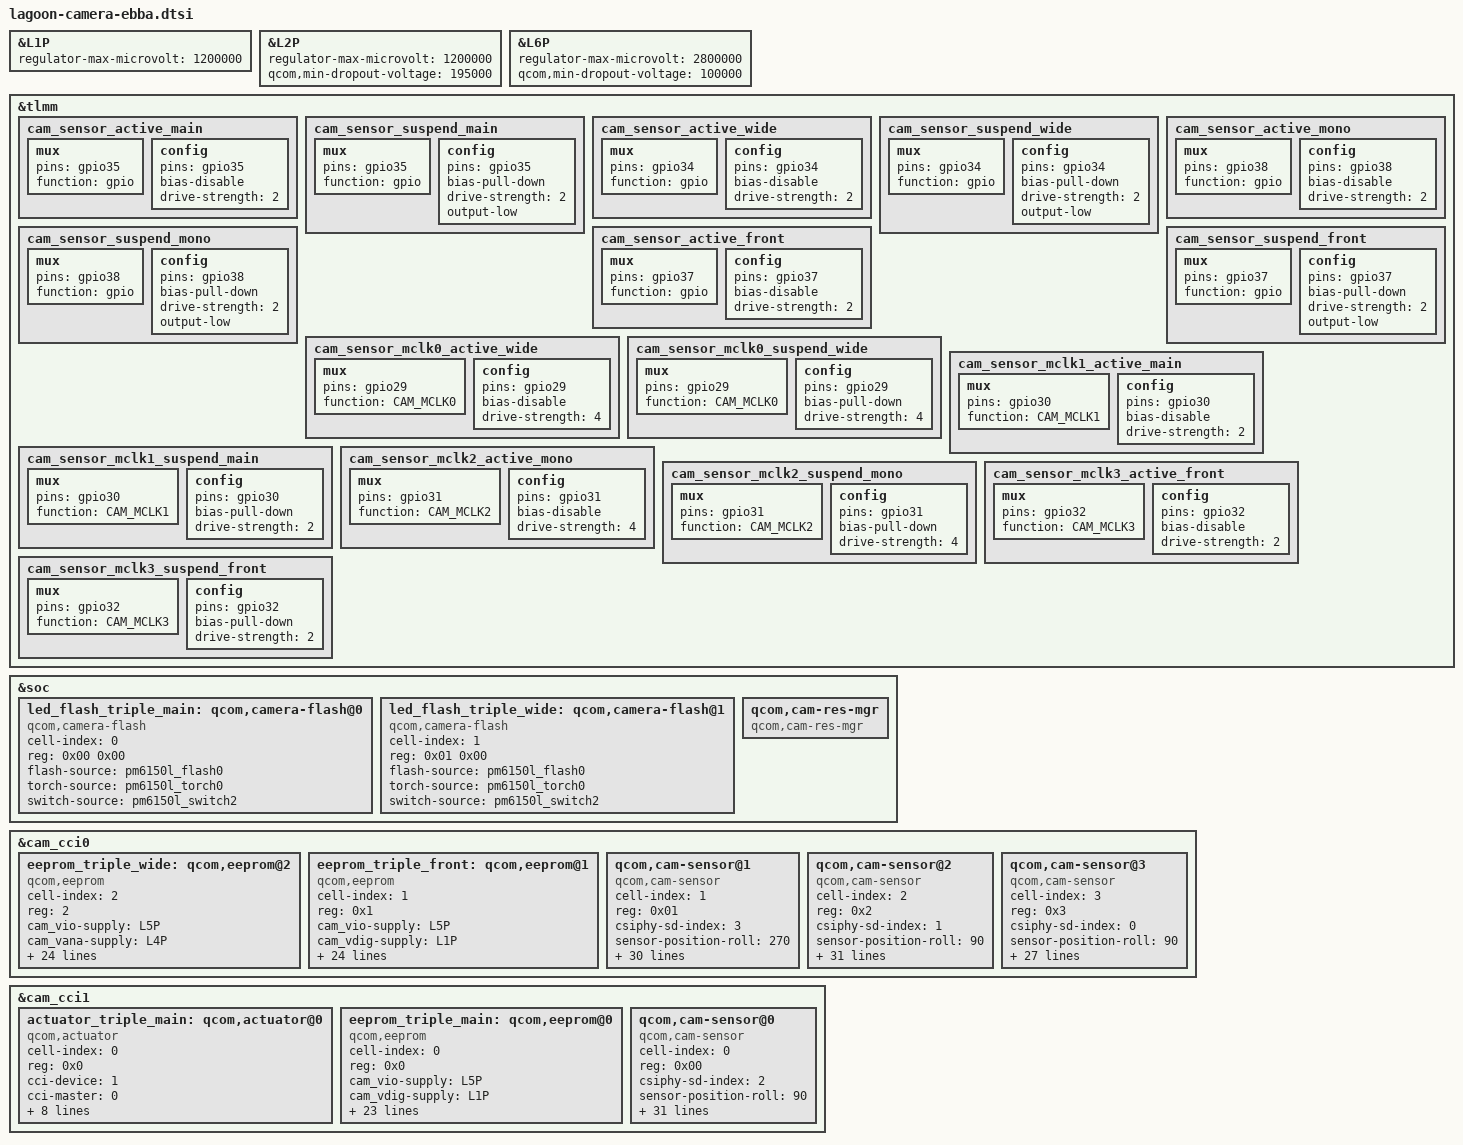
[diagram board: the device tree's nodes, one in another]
#include <dt-bindings/clock/qcom,camcc-lagoon.h>
/*
&pm8008_regulators {
    vdd_l6-supply = <&BOB>;
};
*/
&L1P {
    regulator-max-microvolt = <1200000>;
};

&L2P {
    regulator-max-microvolt = <1200000>;
    qcom,min-dropout-voltage = <195000>;
};

&L6P {
    regulator-max-microvolt = <2800000>;
    qcom,min-dropout-voltage = <100000>;
};

&tlmm {
	cam_sensor_active_main: cam_sensor_active_main {
		/* RESET REAR*/
		mux {
			pins = "gpio35";
			function = "gpio";
		};

		config {
			pins = "gpio35";
			bias-disable; /* No PULL */
			drive-strength = <2>; /* 2 MA */
		};
	};

	cam_sensor_suspend_main: cam_sensor_suspend_main {
		/* RESET REAR*/
		mux {
			pins = "gpio35";
			function = "gpio";
		};

		config {
			pins = "gpio35";
			bias-pull-down; /* PULL DOWN */
			drive-strength = <2>; /* 2 MA */
			output-low;
		};
	};

	cam_sensor_active_wide: cam_sensor_active_wide {
		/* RESET REARAUX */
		mux {
			pins = "gpio34";
			function = "gpio";
		};

		config {
			pins = "gpio34";
			bias-disable; /* No PULL */
			drive-strength = <2>; /* 2 MA */
		};
	};

	cam_sensor_suspend_wide: cam_sensor_suspend_wide {
		/* RESET REARAUX */
		mux {
			pins = "gpio34";
			function = "gpio";
		};

		config {
			pins = "gpio34";
			bias-pull-down; /* PULL DOWN */
			drive-strength = <2>; /* 2 MA */
			output-low;
		};
	};

	cam_sensor_active_mono: cam_sensor_active_mono {
		/* RESET REARAUX1 */
		mux {
			pins = "gpio38";
			function = "gpio";
		};

		config {
			pins = "gpio38";
			bias-disable; /* No PULL */
			drive-strength = <2>; /* 2 MA */
		};
	};

	cam_sensor_suspend_mono: cam_sensor_suspend_mono {
		/* RESET REARAUX1 */
		mux {
			pins = "gpio38";
			function = "gpio";
		};

		config {
			pins = "gpio38";
			bias-pull-down; /* PULL DOWN */
			drive-strength = <2>; /* 2 MA */
			output-low;
		};
	};

	cam_sensor_active_front: cam_sensor_active_front {
		/* RESET FRONT */
		mux {
			pins = "gpio37";
			function = "gpio";
		};

		config {
			pins = "gpio37";
			bias-disable; /* No PULL */
			drive-strength = <2>; /* 2 MA */
		};
	};

	cam_sensor_suspend_front: cam_sensor_suspend_front {
		/* RESET FRONT */
		mux {
			pins = "gpio37";
			function = "gpio";
		};

		config {
			pins = "gpio37";
			bias-pull-down; /* PULL DOWN */
			drive-strength = <2>; /* 2 MA */
			output-low;
		};
	};

	cam_sensor_mclk0_active_wide: cam_sensor_mclk0_active_wide {
		/* MCLK0 */
		mux {
			pins = "gpio29";
			function = "CAM_MCLK0";
		};

		config {
			pins = "gpio29";
			bias-disable; /* No PULL */
			drive-strength = <4>; /* 4 MA */
		};
	};

	cam_sensor_mclk0_suspend_wide: cam_sensor_mclk0_suspend_wide {
		/* MCLK0 */
		mux {
			pins = "gpio29";
			function = "CAM_MCLK0";
		};

		config {
			pins = "gpio29";
			bias-pull-down; /* PULL DOWN */
			drive-strength = <4>; /* 4 MA */
		};
	};

	cam_sensor_mclk1_active_main: cam_sensor_mclk1_active_main {
		/* MCLK1 */
		mux {
			pins = "gpio30";
			function = "CAM_MCLK1";
		};

		config {
			pins = "gpio30";
			bias-disable; /* No PULL */
			drive-strength = <2>; /* 2 MA */
		};
	};

	cam_sensor_mclk1_suspend_main: cam_sensor_mclk1_suspend_main {
		/* MCLK1 */
		mux {
			pins = "gpio30";
			function = "CAM_MCLK1";
		};

		config {
			pins = "gpio30";
			bias-pull-down; /* PULL DOWN */
			drive-strength = <2>; /* 2 MA */
		};
	};

	cam_sensor_mclk2_active_mono: cam_sensor_mclk2_active_mono {
		/* MCLK2 */
		mux {
			pins = "gpio31";
			function = "CAM_MCLK2";
		};

		config {
			pins = "gpio31";
			bias-disable; /* No PULL */
			drive-strength = <4>; /* 4 MA */
		};
	};

	cam_sensor_mclk2_suspend_mono: cam_sensor_mclk2_suspend_mono {
		/* MCLK2 */
		mux {
			pins = "gpio31";
			function = "CAM_MCLK2";
		};

		config {
			pins = "gpio31";
			bias-pull-down; /* PULL DOWN */
			drive-strength = <4>; /* 4 MA */
		};
	};

	cam_sensor_mclk3_active_front: cam_sensor_mclk3_active_front {
		/* MCLK3 */
		mux {
			pins = "gpio32";
			function = "CAM_MCLK3";
		};

		config {
			pins = "gpio32";
			bias-disable; /* No PULL */
			drive-strength = <2>; /* 2 MA */
		};
	};

	cam_sensor_mclk3_suspend_front: cam_sensor_mclk3_suspend_front {
		/* MCLK3 */
		mux {
			pins = "gpio32";
			function = "CAM_MCLK3";
		};

		config {
			pins = "gpio32";
			bias-pull-down; /* PULL DOWN */
			drive-strength = <2>; /* 2 MA */
		};
	};
};

&soc {
	led_flash_triple_main: qcom,camera-flash@0 {
		cell-index = <0>;
		reg = <0x00 0x00>;
		compatible = "qcom,camera-flash";
		flash-source = <&pm6150l_flash0>;
		torch-source = <&pm6150l_torch0>;
		switch-source = <&pm6150l_switch2>;
		status = "ok";
	};

	led_flash_triple_wide: qcom,camera-flash@1 {
		cell-index = <1>;
		reg = <0x01 0x00>;
		compatible = "qcom,camera-flash";
		flash-source = <&pm6150l_flash0>;
		torch-source = <&pm6150l_torch0>;
		switch-source = <&pm6150l_switch2>;
		status = "ok";
	};

	qcom,cam-res-mgr {
		compatible = "qcom,cam-res-mgr";
		status = "ok";
	};
};

&cam_cci0 {
	eeprom_triple_wide: qcom,eeprom@2 {
		cell-index = <2>;
		reg = <2>;
		compatible = "qcom,eeprom";
		cam_vio-supply = <&L5P>;
		cam_vana-supply = <&L4P>;
		cam_vdig-supply = <&L2P>;
		cam_clk-supply = <&cam_cc_titan_top_gdsc>;
		regulator-names = "cam_vio", "cam_vana", "cam_vdig",
			"cam_clk";
		rgltr-cntrl-support;
		rgltr-min-voltage = <1800000 2800000 1200000 0>;
		rgltr-max-voltage = <1800000 2800000 1200000 0>;
		rgltr-load-current = <2000000 2000000 2000000 0>;
		gpio-no-mux = <0>;
		pinctrl-names = "cam_default", "cam_suspend";
		pinctrl-0 = <&cam_sensor_mclk0_active_wide
				 &cam_sensor_active_wide>;
		pinctrl-1 = <&cam_sensor_mclk0_suspend_wide
				 &cam_sensor_suspend_wide>;
		gpios = <&tlmm 29 0>,
			<&tlmm 34 0>;
		gpio-reset = <1>;
		gpio-req-tbl-num = <0 1>;
		gpio-req-tbl-flags = <1 0>;
		gpio-req-tbl-label = "CAMIF_MCLK0",
					"CAM_RESET2";
		sensor-mode = <0>;
		cci-device = <0>;
		cci-master = <1>;
		status = "ok";
		clocks = <&camcc CAM_CC_MCLK0_CLK>;
		clock-names = "cam_clk";
		clock-cntl-level = "turbo";
		clock-rates = <19200000>;
	};

	eeprom_triple_front: qcom,eeprom@1 {
		cell-index = <1>;
		reg = <0x1>;
		compatible = "qcom,eeprom";
		cam_vio-supply = <&L5P>;
		cam_vdig-supply = <&L1P>;
		cam_clk-supply = <&cam_cc_titan_top_gdsc>;
		regulator-names = "cam_vio", "cam_vdig",
			"cam_clk";
		rgltr-cntrl-support;
		pwm-switch;
		rgltr-min-voltage = <1800000 1100000 0>;
		rgltr-max-voltage = <1800000 1100000 0>;
		rgltr-load-current = <2000000 2000000 0>;
		gpio-no-mux = <0>;
		pinctrl-names = "cam_default", "cam_suspend";
		pinctrl-0 = <&cam_sensor_mclk3_active_front
			&cam_sensor_active_front>;
		pinctrl-1 = <&cam_sensor_mclk3_suspend_front
			&cam_sensor_suspend_front>;
		gpios = <&tlmm 32 0>,
			<&tlmm 37 0>;
		gpio-reset = <1>;
		gpio-req-tbl-num = <0 1>;
		gpio-req-tbl-flags = <1 0>;
		gpio-req-tbl-label = "CAMIF_MCLK3",
					"CAM_RESET1";
		sensor-position = <1>;
		sensor-mode = <0>;
		cci-device = <0>;
		cci-master = <0>;
		status = "ok";
		clocks = <&camcc CAM_CC_MCLK3_CLK>;
		clock-names = "cam_clk";
		clock-cntl-level = "turbo";
		clock-rates = <19200000>;
	};

	/* front sensor */
	qcom,cam-sensor@1 {
		cell-index = <1>;
		compatible = "qcom,cam-sensor";
		reg = <0x01>;
		csiphy-sd-index = <3>;
		sensor-position-roll = <270>;
		sensor-position-pitch = <0>;
		sensor-position-yaw = <0>;
		eeprom-src = <&eeprom_triple_front>;
		cam_vio-supply = <&L5P>;
		cam_vana-supply = <&L7P>;
		cam_vdig-supply = <&L1P>;
		cam_clk-supply = <&cam_cc_titan_top_gdsc>;
		regulator-names = "cam_vio", "cam_vana", "cam_vdig",
			"cam_clk";
		rgltr-cntrl-support;
		pwm-switch;
		rgltr-min-voltage = <1800000 2800000 1100000 0>;
		rgltr-max-voltage = <1800000 2800000 1100000 0>;
		rgltr-load-current = <2000000 2000000 2000000 0>;
		gpio-no-mux = <0>;
		pinctrl-names = "cam_default", "cam_suspend";
		pinctrl-0 = <&cam_sensor_mclk3_active_front
			&cam_sensor_active_front>;
		pinctrl-1 = <&cam_sensor_mclk3_suspend_front
			&cam_sensor_suspend_front>;
		gpios = <&tlmm 32 0>,
			<&tlmm 37 0>;
		gpio-reset = <1>;
		gpio-req-tbl-num = <0 1>;
		gpio-req-tbl-flags = <1 0>;
		gpio-req-tbl-label = "CAMIF_MCLK3",
					"CAM_RESET1";
		sensor-mode = <0>;
		cci-device = <0>;
		cci-master = <0>;
		status = "ok";
		clocks = <&camcc CAM_CC_MCLK3_CLK>;
		clock-names = "cam_clk";
		clock-cntl-level = "turbo";
		clock-rates = <19200000>;
	};

	/* wide sensor */
	qcom,cam-sensor@2 {
		cell-index = <2>;
		compatible = "qcom,cam-sensor";
		reg = <0x2>;
		csiphy-sd-index = <1>;
		sensor-position-roll = <90>;
		sensor-position-pitch = <0>;
		sensor-position-yaw = <180>;
		eeprom-src = <&eeprom_triple_wide>;
		led-flash-src = <&led_flash_triple_wide>;
		cam_vio-supply = <&L5P>;
		cam_vana-supply = <&L4P>;
		cam_vdig-supply = <&L2P>;
		cam_clk-supply = <&cam_cc_titan_top_gdsc>;
		regulator-names = "cam_vio", "cam_vana", "cam_vdig",
			"cam_clk";
		rgltr-cntrl-support;
		pwm-switch;
		rgltr-min-voltage = <1800000 2800000 1200000 0>;
		rgltr-max-voltage = <1800000 2800000 1200000 0>;
		rgltr-load-current = <2000000 2000000 2000000 0>;
		gpio-no-mux = <0>;
		pinctrl-names = "cam_default", "cam_suspend";
		pinctrl-0 = <&cam_sensor_mclk0_active_wide
				 &cam_sensor_active_wide>;
		pinctrl-1 = <&cam_sensor_mclk0_suspend_wide
				 &cam_sensor_suspend_wide>;
		gpios = <&tlmm 29 0>,
			<&tlmm 34 0>;
		gpio-reset = <1>;
		gpio-req-tbl-num = <0 1>;
		gpio-req-tbl-flags = <1 0>;
		gpio-req-tbl-label = "CAMIF_MCLK0",
					"CAM_RESET2";
		sensor-mode = <0>;
		cci-device = <0>;
		cci-master = <1>;
		status = "ok";
		clocks = <&camcc CAM_CC_MCLK0_CLK>;
		clock-names = "cam_clk";
		clock-cntl-level = "turbo";
		clock-rates = <19200000>;
	};

	/* mono sensor */
	qcom,cam-sensor@3 {
		cell-index = <3>;
		compatible = "qcom,cam-sensor";
		reg = <0x3>;
		csiphy-sd-index = <0>;
		sensor-position-roll = <90>;
		sensor-position-pitch = <0>;
		sensor-position-yaw = <180>;
		cam_vio-supply = <&L5P>;
		cam_vana-supply = <&L4P>;
		cam_clk-supply = <&cam_cc_titan_top_gdsc>;
		regulator-names = "cam_vio", "cam_vana", "cam_clk";
		rgltr-cntrl-support;
		pwm-switch;
		rgltr-min-voltage = <1800000 2800000 0>;
		rgltr-max-voltage = <1800000 2800000 0>;
		rgltr-load-current = <2000000 2000000 0>;
		gpio-no-mux = <0>;
		pinctrl-names = "cam_default", "cam_suspend";
		pinctrl-0 = <&cam_sensor_mclk2_active_mono
				&cam_sensor_active_mono>;
		pinctrl-1 = <&cam_sensor_mclk2_suspend_mono
				&cam_sensor_suspend_mono>;
		gpios = <&tlmm 31 0>,
			<&tlmm 38 0>;
		gpio-standby = <1>;//PWDN
		gpio-req-tbl-num = <0 1>;
		gpio-req-tbl-flags = <1 0>;
		gpio-req-tbl-label = "CAMIF_MCLK2",
					"CAM_STANDBY";
		sensor-mode = <0>;
		cci-device = <0>;
		cci-master = <1>;
		status = "ok";
		clocks = <&camcc CAM_CC_MCLK2_CLK>;
		clock-names = "cam_clk";
		clock-cntl-level = "turbo";
		clock-rates = <19200000>;
	};
};

&cam_cci1 {
	actuator_triple_main: qcom,actuator@0 {
		cell-index = <0>;
		reg = <0x0>;
		compatible = "qcom,actuator";
		cci-device = <1>;
		cci-master = <0>;
		cam_vio-supply = <&L5P>;
		cam_vaf-supply = <&L6P>;
		regulator-names = "cam_vio", "cam_vaf";
		rgltr-cntrl-support;
		need-check-pid;
		rgltr-min-voltage = <1800000 2800000>;
		rgltr-max-voltage = <1800000 2800000>;
		rgltr-load-current = <2000000 100000>;
		status = "ok";
	};

	eeprom_triple_main: qcom,eeprom@0 {
		cell-index = <0>;
		reg = <0x0>;
		compatible = "qcom,eeprom";
		cam_vio-supply = <&L5P>;
		cam_vdig-supply = <&L1P>;
		cam_clk-supply = <&cam_cc_titan_top_gdsc>;
		regulator-names = "cam_vio", "cam_vdig",
			"cam_clk";
		rgltr-cntrl-support;
		rgltr-min-voltage = <1800000 1100000 0>;
		rgltr-max-voltage = <1800000 1100000 0>;
		rgltr-load-current = <2000000 2000000 0>;
		gpio-no-mux = <0>;
		pinctrl-names = "cam_default", "cam_suspend";
		pinctrl-0 = <&cam_sensor_mclk1_active_main
				 &cam_sensor_active_main>;
		pinctrl-1 = <&cam_sensor_mclk1_suspend_main
				 &cam_sensor_suspend_main>;
		gpios = <&tlmm 30 0>,
			<&tlmm 35 0>;
		gpio-reset = <1>;
		gpio-req-tbl-num = <0 1>;
		gpio-req-tbl-flags = <1 0>;
		gpio-req-tbl-label = "CAMIF_MCLK1",
					"CAM_RESET0";
		sensor-position = <0>;
		sensor-mode = <0>;
		cci-device = <1>;
		cci-master = <0>;
		status = "ok";
		clocks = <&camcc CAM_CC_MCLK1_CLK>;
		clock-names = "cam_clk";
		clock-cntl-level = "turbo";
		clock-rates = <19200000>;
	};

	/* main sensor */
	qcom,cam-sensor@0 {
		cell-index = <0>;
		compatible = "qcom,cam-sensor";
		reg = <0x00>;
		csiphy-sd-index = <2>;
		sensor-position-roll = <90>;
		sensor-position-pitch = <0>;
		sensor-position-yaw = <180>;
		led-flash-src = <&led_flash_triple_main>;
		actuator-src = <&actuator_triple_main>;
		eeprom-src = <&eeprom_triple_main>;
		cam_vio-supply = <&L5P>;
		cam_vana-supply = <&L3P>;
		cam_vdig-supply = <&L1P>;
		cam_clk-supply = <&cam_cc_titan_top_gdsc>;
		regulator-names = "cam_vio", "cam_vana", "cam_vdig",
			"cam_clk";
		rgltr-cntrl-support;
		rgltr-min-voltage = <1800000 2800000 1100000 0>;
		rgltr-max-voltage = <1800000 2800000 1100000 0>;
		rgltr-load-current = <2000000 2000000 2000000 0>;
		gpio-no-mux = <0>;
		pinctrl-names = "cam_default", "cam_suspend";
		pinctrl-0 = <&cam_sensor_mclk1_active_main
				 &cam_sensor_active_main>;
		pinctrl-1 = <&cam_sensor_mclk1_suspend_main
				 &cam_sensor_suspend_main>;
		gpios = <&tlmm 30 0>,
			<&tlmm 35 0>;
		gpio-reset = <1>;
		gpio-req-tbl-num = <0 1>;
		gpio-req-tbl-flags = <1 0>;
		gpio-req-tbl-label = "CAMIF_MCLK1",
					"CAM_RESET0";
		sensor-mode = <0>;
		cci-device = <1>;
		cci-master = <0>;
		status = "ok";
		clocks = <&camcc CAM_CC_MCLK1_CLK>;
		clock-names = "cam_clk";
		clock-cntl-level = "turbo";
		clock-rates = <19200000>;
	};
};
